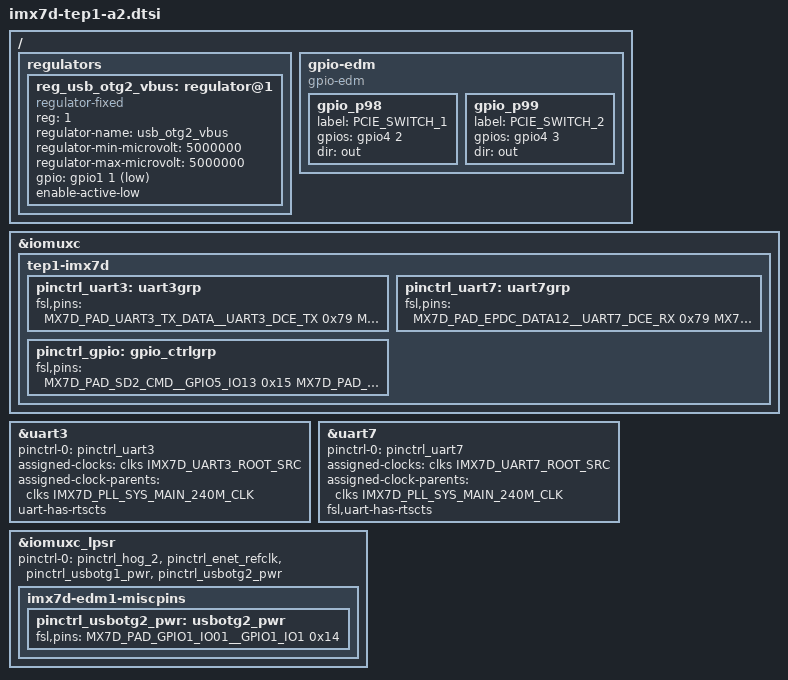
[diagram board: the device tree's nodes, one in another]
/*
 * Copyright 2016 Technexion Ltd.
 *
 * Author: Alvin Chen<alvin.chen@technexion.com>
 *
 * This program is free software; you can redistribute it and/or modify
 * it under the terms of the GNU General Public License version 2 as
 * published by the Free Software Foundation.
 *
 */

#include <dt-bindings/input/input.h>
#include <dt-bindings/gpio/gpio.h>
#include "imx7d-tep1.dtsi"

/ {
	regulators {
		reg_usb_otg2_vbus: regulator@1 {
			compatible = "regulator-fixed";
			reg = <1>;
			regulator-name = "usb_otg2_vbus";
			regulator-min-microvolt = <5000000>;
			regulator-max-microvolt = <5000000>;
			gpio = <&gpio1 1 GPIO_ACTIVE_LOW>;
			enable-active-low;
		};
	};

	gpio-edm {
		compatible = "gpio-edm";
		gpio_p98 {
			label = "PCIE_SWITCH_1";
			gpios = <&gpio4 2 0>;
			dir   = "out";
		};
		gpio_p99 {
			label = "PCIE_SWITCH_2";
			gpios = <&gpio4 3 0>;
			dir   = "out";
		};
	};
};

&iomuxc {
	tep1-imx7d {
		pinctrl_uart3: uart3grp {
			fsl,pins = <
				MX7D_PAD_UART3_TX_DATA__UART3_DCE_TX	0x79
				MX7D_PAD_UART3_RX_DATA__UART3_DCE_RX	0x79
				MX7D_PAD_UART3_RTS_B__UART3_DCE_RTS	0x79
				MX7D_PAD_UART3_CTS_B__UART3_DCE_CTS	0x79
			>;
		};

		pinctrl_uart7: uart7grp {
			fsl,pins = <
				MX7D_PAD_EPDC_DATA12__UART7_DCE_RX	0x79
				MX7D_PAD_EPDC_DATA13__UART7_DCE_TX	0x79
				MX7D_PAD_EPDC_DATA14__UART7_DCE_RTS	0x79
				MX7D_PAD_EPDC_DATA15__UART7_DCE_CTS	0x79
			>;
		};

		pinctrl_gpio: gpio_ctrlgrp {
			fsl,pins = <
				MX7D_PAD_SD2_CMD__GPIO5_IO13		0x15
				MX7D_PAD_SD1_RESET_B__GPIO5_IO2		0x15
				MX7D_PAD_EPDC_DATA04__GPIO2_IO4		0x15
				MX7D_PAD_SD2_CLK__GPIO5_IO12		0x15
				MX7D_PAD_SAI2_TX_DATA__GPIO6_IO22 	0x15
				MX7D_PAD_I2C4_SDA__GPIO4_IO15		0x15	/* fec power */
				MX7D_PAD_SAI2_RX_DATA__GPIO6_IO21	0x15	/* M2 power */
				MX7D_PAD_UART2_RX_DATA__GPIO4_IO2	0x15
				MX7D_PAD_UART2_TX_DATA__GPIO4_IO3	0x15
			>;
		};
	};
};

&uart3 {
	pinctrl-names = "default";
	pinctrl-0 = <&pinctrl_uart3>;
	assigned-clocks = <&clks IMX7D_UART3_ROOT_SRC>;
	assigned-clock-parents = <&clks IMX7D_PLL_SYS_MAIN_240M_CLK>;
	uart-has-rtscts;
	status = "okay";
};

&uart7 {
	pinctrl-names = "default";
	pinctrl-0 = <&pinctrl_uart7>;
	assigned-clocks = <&clks IMX7D_UART7_ROOT_SRC>;
	assigned-clock-parents = <&clks IMX7D_PLL_SYS_MAIN_240M_CLK>;
	fsl,uart-has-rtscts;
	status = "okay";
};

&iomuxc_lpsr {
	pinctrl-0 = <&pinctrl_hog_2 &pinctrl_enet_refclk &pinctrl_usbotg1_pwr &pinctrl_usbotg2_pwr>;

	imx7d-edm1-miscpins {
		pinctrl_usbotg2_pwr: usbotg2_pwr {
			fsl,pins = <
				MX7D_PAD_GPIO1_IO01__GPIO1_IO1		0x14
			>;
		};
	};
};
